# STM32F7x6 register map
File version: 1.6
CPU: CM7 r0p1, little endian, MPU, FPU, 4 interrupt priority bits
Registers are 32-bit, read-write, reset 0x0 unless marked. A register's access mark holds for its fields unless they carry their own. Offsets are from the block's base; [hi:lo] are bit positions.

## Ethernet_DMA — Ethernet: DMA controller operation
Base 0x40029000
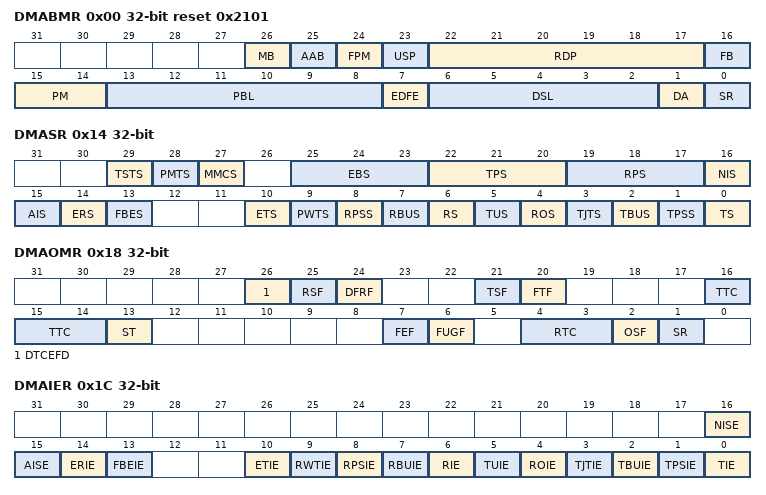
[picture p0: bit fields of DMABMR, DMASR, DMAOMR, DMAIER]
0x00 DMABMR reset 0x2101 — Ethernet DMA bus mode register
  [26] MB — Mixed burst
    0=Normal (Fixed burst transfers (INCRx and SINGLE) for burst lengths of 16 and below); 1=Mixed (If FB is low, start all bursts greater than 16 with INCR (undefined burst))
  [25] AAB — Address-aligned beats
    0=Unaligned (Bursts are not aligned); 1=Aligned (Align bursts to start address LS bits. First burst alignment depends on FB bit)
  [24] FPM — 4xPBL mode
    0=PBL values used as-is; 1=x4 (PBL values multiplied by 4)
  [23] USP — Use separate PBL
    0=Combined (PBL value used for both Rx and Tx DMA); 1=Separate (RxDMA uses RDP value, TxDMA uses PBL value)
  [22:17] RDP — Rx DMA PBL
    1=1 beat per RxDMA transaction; 2=2 beats per RxDMA transaction; 4=4 beats per RxDMA transaction; 8=8 beats per RxDMA transaction; 16=16 beats per RxDMA transaction; 32=32 beats per RxDMA transaction
  [16] FB — Fixed burst
    0=Variable (AHB uses SINGLE and INCR burst transfers); 1=Fixed (AHB uses only fixed burst transfers)
  [15:14] PM — Rx-Tx priority ratio
    0=OneToOne (RxDMA priority over TxDMA is 1:1); 1=TwoToOne (RxDMA priority over TxDMA is 2:1); 2=ThreeToOne (RxDMA priority over TxDMA is 3:1); 3=FourToOne (RxDMA priority over TxDMA is 4:1)
  [13:8] PBL — Programmable burst length
    1=Maximum of 1 beat per DMA transaction; 2=Maximum of 2 beats per DMA transaction; 4=Maximum of 4 beats per DMA transaction; 8=Maximum of 8 beats per DMA transaction; 16=Maximum of 16 beats per DMA transaction; 32=Maximum of 32 beats per DMA transaction
  [7] EDFE — Enhanced descriptor format enable
    0=Disabled (Normal descriptor format); 1=Enabled (Enhanced 32-byte descriptor format, required for timestamping and IPv4 checksum offload)
  [6:2] DSL — Descriptor skip length
  [1] DA — DMA arbitration
    0=Round-robin with Rx:Tx priority given by PM; 1=RxPriority (Rx has priority over Tx)
  [0] SR — Software reset
    1=Reset all MAC subsystem internal registers and logic. Cleared automatically
0x04 DMATPDR — Ethernet DMA transmit poll demand register
  [31:0] TPD — Transmit poll demand
    0=Poll the transmit descriptor list
0x08 DMARPDR — EHERNET DMA receive poll demand register
  [31:0] RPD — Receive poll demand
    0=Poll the receive descriptor list
0x0C DMARDLAR — Ethernet DMA receive descriptor list address register
  [31:0] SRL — Start of receive list
0x10 DMATDLAR — Ethernet DMA transmit descriptor list address register
  [31:0] STL — Start of transmit list
0x14 DMASR access per field — Ethernet DMA status register
  [29] TSTS ro — Time stamp trigger status
  [28] PMTS ro — PMT status
  [27] MMCS ro — MMC status
  [25:23] EBS ro — Error bits status
  [22:20] TPS ro — Transmit process state
    on read: 0=Stopped, Reset or Stop Transmit command issued; 1=Running, fetching transmit transfer descriptor; 2=Running, waiting for status; 3=Running, reading data from host memory buffer; 6=Suspended, transmit descriptor unavailable or transmit buffer underflow; 7=Running, closing transmit descriptor
  [19:17] RPS ro — Receive process state
    on read: 0=Stopped, reset or Stop Receive command issued; 1=Running, fetching receive transfer descriptor; 3=Running, waiting for receive packet; 4=Suspended, receive descriptor unavailable; 7=Running, writing data to host memory buffer
  [16] NIS rw — Normal interrupt summary
  [15] AIS rw — Abnormal interrupt summary
  [14] ERS rw — Early receive status
  [13] FBES rw — Fatal bus error status
  [10] ETS rw — Early transmit status
  [9] PWTS rw
  [8] RPSS rw — Receive process stopped status
  [7] RBUS rw — Receive buffer unavailable status
  [6] RS rw — Receive status
  [5] TUS rw — Transmit underflow status
  [4] ROS rw — Receive overflow status
  [3] TJTS rw — Transmit jabber timeout status
  [2] TBUS rw — Transmit buffer unavailable status
  [1] TPSS rw — Transmit process stopped status
  [0] TS rw — Transmit status
0x18 DMAOMR — Ethernet DMA operation mode register
  [26] DTCEFD — Dropping of TCP/IP checksum error frames disable
    0=Enabled (Drop frames with errors only in the receive checksum offload engine); 1=Disabled (Do not drop frames that only have errors in the receive checksum offload engine)
  [25] RSF — Receive store and forward
    0=CutThrough (Rx FIFO operates in cut-through mode, subject to RTC bits); 1=StoreForward (Frames are read from Rx FIFO after complete frame has been written)
  [24] DFRF — Disable flushing of received frames
  [21] TSF — Transmit store and forward
    0=CutThrough (Transmission starts when the frame size in the Tx FIFO exceeds TTC threshold); 1=StoreForward (Transmission starts when a full frame is in the Tx FIFO)
  [20] FTF — Flush transmit FIFO
    1=Flush (Transmit FIFO controller logic is reset to its default values. Cleared automatically)
  [16:14] TTC — Transmit threshold control
    0=64 bytes; 1=128 bytes; 2=192 bytes; 3=256 bytes; 4=40 bytes; 5=32 bytes; 6=24 bytes; 7=16 bytes
  [13] ST — Start/stop transmission
    0=Stopped (Transmission is placed in the Stopped state); 1=Started (Transmission is placed in Running state)
  [7] FEF — Forward error frames
    0=Drop (Rx FIFO drops frames with error status); 1=Forward (All frames except runt error frames are forwarded to the DMA)
  [6] FUGF — Forward undersized good frames
    0=Drop (Rx FIFO drops all frames of less than 64 bytes); 1=Forward (Rx FIFO forwards undersized frames)
  [4:3] RTC — Receive threshold control
    0=64 bytes; 1=32 bytes; 2=96 bytes; 3=128 bytes
  [2] OSF — Operate on second frame
  [1] SR — Start/stop receive
    0=Stopped (Reception is stopped after transfer of the current frame); 1=Started (Reception is placed in the Running state)
0x1C DMAIER — Ethernet DMA interrupt enable register
  [16] NISE — Normal interrupt summary enable
  [15] AISE — Abnormal interrupt summary enable
  [14] ERIE — Early receive interrupt enable
  [13] FBEIE — Fatal bus error interrupt enable
  [10] ETIE — Early transmit interrupt enable
  [9] RWTIE — Receive watchdog timeout interrupt enable
  [8] RPSIE — Receive process stopped interrupt enable
  [7] RBUIE — Receive buffer unavailable interrupt enable
  [6] RIE — Receive interrupt enable
  [5] TUIE — Transmit underflow interrupt enable
  [4] ROIE — Receive overflow interrupt enable
  [3] TJTIE — Transmit jabber timeout interrupt enable
  [2] TBUIE — Transmit buffer unavailable interrupt enable
  [1] TPSIE — Transmit process stopped interrupt enable
  [0] TIE — Transmit interrupt enable
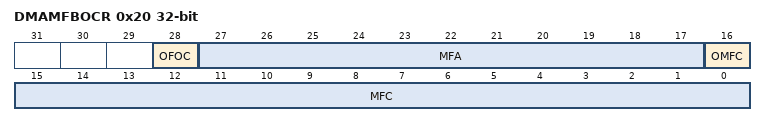
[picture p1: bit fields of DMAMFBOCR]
0x20 DMAMFBOCR — Ethernet DMA missed frame and buffer overflow counter register
  [28] OFOC — Overflow bit for FIFO overflow counter
  [27:17] MFA — Missed frames by the application
  [16] OMFC — Overflow bit for missed frame counter
  [15:0] MFC — Missed frames by the controller
0x24 DMARSWTR — Ethernet DMA receive status watchdog timer register
  [7:0] RSWTC — Receive status watchdog timer count
0x48 DMACHTDR ro — Ethernet DMA current host transmit descriptor register
  [31:0] HTDAP — Host transmit descriptor address pointer
0x4C DMACHRDR ro — Ethernet DMA current host receive descriptor register
  [31:0] HRDAP — Host receive descriptor address pointer
0x50 DMACHTBAR ro — Ethernet DMA current host transmit buffer address register
  [31:0] HTBAP — Host transmit buffer address pointer
0x54 DMACHRBAR ro — Ethernet DMA current host receive buffer address register
  [31:0] HRBAP — Host receive buffer address pointer
